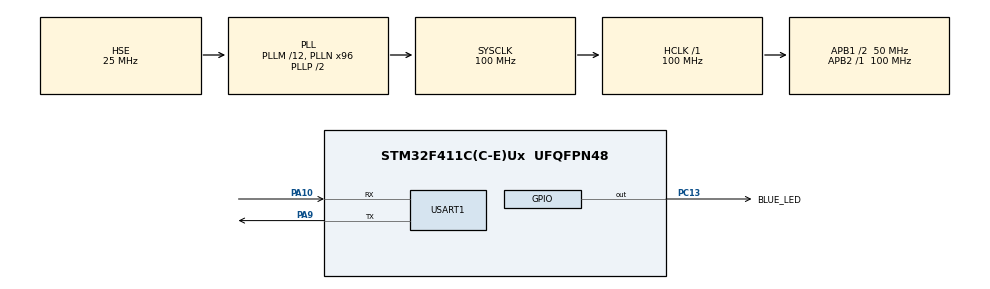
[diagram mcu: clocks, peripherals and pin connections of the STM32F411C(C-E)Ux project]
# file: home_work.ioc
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FREERTOS.Tasks01=defaultTask,24,128,StartDefaultTask,Default,NULL,Dynamic,NULL,NULL
Mcu.Family=STM32F4
Mcu.Name=STM32F411C(C-E)Ux
Mcu.Package=UFQFPN48
NVIC.PriorityGroup=NVIC_PRIORITYGROUP_4
NVIC.TIM1_UP_TIM10_IRQn=true\:0\:0\:false\:false\:true\:false\:false\:true
NVIC.TimeBase=TIM1_UP_TIM10_IRQn
NVIC.TimeBaseIP=TIM1
PA10.Mode=Asynchronous
PA10.Signal=USART1_RX
PA13.Mode=Serial_Wire
PA13.Signal=SYS_JTMS-SWDIO
PA14.Mode=Serial_Wire
PA14.Signal=SYS_JTCK-SWCLK
PA9.Mode=Asynchronous
PA9.Signal=USART1_TX
PC13-ANTI_TAMP.GPIO_Label=BLUE_LED
PC13-ANTI_TAMP.Signal=GPIO_Output
PC14-OSC32_IN.Mode=LSE-External-Oscillator
PC14-OSC32_IN.Signal=RCC_OSC32_IN
PC15-OSC32_OUT.Mode=LSE-External-Oscillator
PC15-OSC32_OUT.Signal=RCC_OSC32_OUT
PH0\ -\ OSC_IN.Mode=HSE-External-Oscillator
PH0\ -\ OSC_IN.Signal=RCC_OSC_IN
PH1\ -\ OSC_OUT.Mode=HSE-External-Oscillator
PH1\ -\ OSC_OUT.Signal=RCC_OSC_OUT
ProjectManager.HeapSize=0x200
ProjectManager.StackSize=0x400
ProjectManager.TargetToolchain=MDK-ARM V5.27
RCC.48MHZClocksFreq_Value=50000000
RCC.AHBFreq_Value=100000000
RCC.APB1CLKDivider=RCC_HCLK_DIV2
RCC.APB1Freq_Value=50000000
RCC.APB1TimFreq_Value=100000000
RCC.APB2Freq_Value=100000000
RCC.APB2TimFreq_Value=100000000
RCC.CortexFreq_Value=100000000
RCC.HCLKFreq_Value=100000000
RCC.HSE_VALUE=25000000
RCC.HSI_VALUE=16000000
RCC.PLLM=12
RCC.PLLN=96
RCC.PLLSourceVirtual=RCC_PLLSOURCE_HSE
RCC.SYSCLKFreq_VALUE=100000000
RCC.SYSCLKSource=RCC_SYSCLKSOURCE_PLLCLK
RCC.VCOOutputFreq_Value=200000000
USART1.VirtualMode=VM_ASYNC
VP_FREERTOS_VS_CMSIS_V2.Mode=CMSIS_V2
VP_SYS_VS_tim1.Mode=TIM1
board=custom

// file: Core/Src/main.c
/* USER CODE BEGIN Header */
/**
  ******************************************************************************
  * @file           : main.c
  * @brief          : Main program body
  ******************************************************************************
  * @attention
  *
  * <h2><center>&copy; Copyright (c) 2025 STMicroelectronics.
  * All rights reserved.</center></h2>
  *
  * This software component is licensed by ST under BSD 3-Clause license,
  * the "License"; You may not use this file except in compliance with the
  * License. You may obtain a copy of the License at:
  *                        opensource.org/licenses/BSD-3-Clause
  *
  ******************************************************************************
  */
/* USER CODE END Header */
#include "main.h"
#include "cmsis_os.h"

UART_HandleTypeDef huart1;

/* Definitions for defaultTask */
osThreadId_t defaultTaskHandle;
const osThreadAttr_t defaultTask_attributes = {
  .name = "defaultTask",
  .priority = (osPriority_t) osPriorityNormal,
  .stack_size = 128 * 4
};
/* USER CODE BEGIN PV */

// printf 串口重定向
#include "stdio.h"

#ifdef __GNUC__
    #define PUTCHAR_PROTOTYPE int __io_putchar(int ch)
#else
    #define PUTCHAR_PROTOTYPE int fputc(int ch, FILE *f)
#endif

// fputc 接口本身在 micro_lib 里面实现了，所以我们只需要重定向这个接口即可
PUTCHAR_PROTOTYPE
{
    HAL_UART_Transmit(&huart1, (uint8_t *)&ch, 1, 0xFFFF);
    return ch;
}
/* USER CODE END PV */

void SystemClock_Config(void);
static void MX_GPIO_Init(void);
static void MX_USART1_UART_Init(void);
void StartDefaultTask(void *argument);

int main(void)
{

  /* MCU Configuration--------------------------------------------------------*/

  /* Reset of all peripherals, Initializes the Flash interface and the Systick. */
  HAL_Init();

  /* Configure the system clock */
  SystemClock_Config();

  /* Initialize all configured peripherals */
  MX_GPIO_Init();
  MX_USART1_UART_Init();

  /* Init scheduler */
  osKernelInitialize();

  /* Create the thread(s) */
  /* creation of defaultTask */
  defaultTaskHandle = osThreadNew(StartDefaultTask, NULL, &defaultTask_attributes);

  /* Start scheduler */
  osKernelStart();

  /* We should never get here as control is now taken by the scheduler */
  /* Infinite loop */
  while (1)
  {

  }
}

void SystemClock_Config(void)
{
  RCC_OscInitTypeDef RCC_OscInitStruct = {0};
  RCC_ClkInitTypeDef RCC_ClkInitStruct = {0};

  /** Configure the main internal regulator output voltage
  */
  __HAL_RCC_PWR_CLK_ENABLE();
  __HAL_PWR_VOLTAGESCALING_CONFIG(PWR_REGULATOR_VOLTAGE_SCALE1);
  /** Initializes the RCC Oscillators according to the specified parameters
  * in the RCC_OscInitTypeDef structure.
  */
  RCC_OscInitStruct.OscillatorType = RCC_OSCILLATORTYPE_HSE;
  RCC_OscInitStruct.HSEState = RCC_HSE_ON;
  RCC_OscInitStruct.PLL.PLLState = RCC_PLL_ON;
  RCC_OscInitStruct.PLL.PLLSource = RCC_PLLSOURCE_HSE;
  RCC_OscInitStruct.PLL.PLLM = 12;
  RCC_OscInitStruct.PLL.PLLN = 96;
  RCC_OscInitStruct.PLL.PLLP = RCC_PLLP_DIV2;
  RCC_OscInitStruct.PLL.PLLQ = 4;
  if (HAL_RCC_OscConfig(&RCC_OscInitStruct) != HAL_OK)
  {
    Error_Handler();
  }
  /** Initializes the CPU, AHB and APB buses clocks
  */
  RCC_ClkInitStruct.ClockType = RCC_CLOCKTYPE_HCLK|RCC_CLOCKTYPE_SYSCLK
                              |RCC_CLOCKTYPE_PCLK1|RCC_CLOCKTYPE_PCLK2;
  RCC_ClkInitStruct.SYSCLKSource = RCC_SYSCLKSOURCE_PLLCLK;
  RCC_ClkInitStruct.AHBCLKDivider = RCC_SYSCLK_DIV1;
  RCC_ClkInitStruct.APB1CLKDivider = RCC_HCLK_DIV2;
  RCC_ClkInitStruct.APB2CLKDivider = RCC_HCLK_DIV1;

  if (HAL_RCC_ClockConfig(&RCC_ClkInitStruct, FLASH_LATENCY_3) != HAL_OK)
  {
    Error_Handler();
  }
}

static void MX_USART1_UART_Init(void)
{

  huart1.Instance = USART1;
  huart1.Init.BaudRate = 115200;
  huart1.Init.WordLength = UART_WORDLENGTH_8B;
  huart1.Init.StopBits = UART_STOPBITS_1;
  huart1.Init.Parity = UART_PARITY_NONE;
  huart1.Init.Mode = UART_MODE_TX_RX;
  huart1.Init.HwFlowCtl = UART_HWCONTROL_NONE;
  huart1.Init.OverSampling = UART_OVERSAMPLING_16;
  if (HAL_UART_Init(&huart1) != HAL_OK)
  {
    Error_Handler();
  }

}

static void MX_GPIO_Init(void)
{
  GPIO_InitTypeDef GPIO_InitStruct = {0};

  /* GPIO Ports Clock Enable */
  __HAL_RCC_GPIOC_CLK_ENABLE();
  __HAL_RCC_GPIOH_CLK_ENABLE();
  __HAL_RCC_GPIOA_CLK_ENABLE();

  /*Configure GPIO pin Output Level */
  HAL_GPIO_WritePin(BLUE_LED_GPIO_Port, BLUE_LED_Pin, GPIO_PIN_RESET);

  /*Configure GPIO pin : BLUE_LED_Pin */
  GPIO_InitStruct.Pin = BLUE_LED_Pin;
  GPIO_InitStruct.Mode = GPIO_MODE_OUTPUT_PP;
  GPIO_InitStruct.Pull = GPIO_NOPULL;
  GPIO_InitStruct.Speed = GPIO_SPEED_FREQ_LOW;
  HAL_GPIO_Init(BLUE_LED_GPIO_Port, &GPIO_InitStruct);

}

void StartDefaultTask(void *argument)
{
  /* USER CODE BEGIN 5 */
  /* Infinite loop */
  for(;;)
  {
    HAL_GPIO_WritePin(GPIOC, GPIO_PIN_13, GPIO_PIN_SET);
    osDelay(500);
    HAL_GPIO_WritePin(GPIOC, GPIO_PIN_13, GPIO_PIN_RESET);
    osDelay(500);

    printf("Hello World!\r\n");
  }
  /* USER CODE END 5 */
}

 /**
  * @brief  Period elapsed callback in non blocking mode
  * @note   This function is called  when TIM1 interrupt took place, inside
  * HAL_TIM_IRQHandler(). It makes a direct call to HAL_IncTick() to increment
  * a global variable "uwTick" used as application time base.
  * @param  htim : TIM handle
  * @retval None
  */
void HAL_TIM_PeriodElapsedCallback(TIM_HandleTypeDef *htim)
{
  if (htim->Instance == TIM1) {
    HAL_IncTick();
  }
}

void Error_Handler(void)
{
  __disable_irq();
  while (1)
  {
  }
}

/************************ (C) COPYRIGHT STMicroelectronics *****END OF FILE****/
